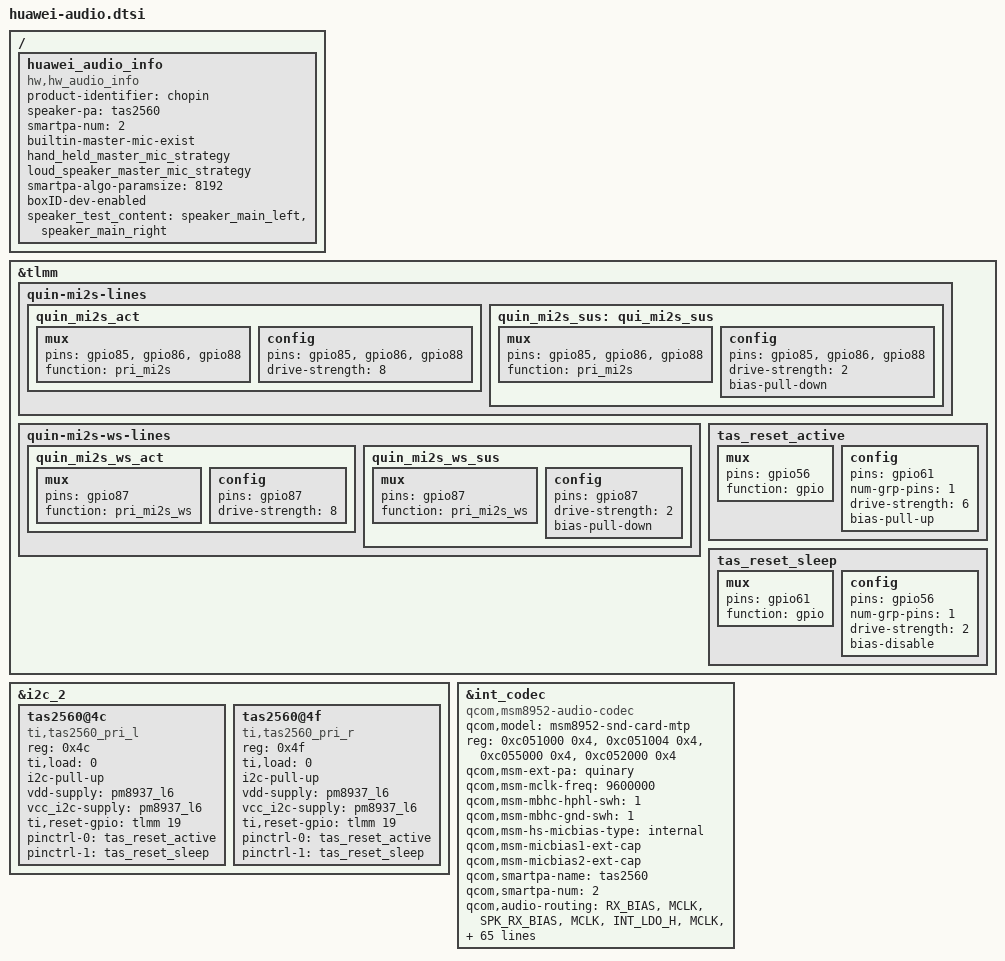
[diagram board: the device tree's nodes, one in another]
/*
 * Copyright (c) 2016, The Linux Foundation. All rights reserved.
 *
 * This program is free software; you can redistribute it and/or modify
 * it under the terms of the GNU General Public License version 2 and
 * only version 2 as published by the Free Software Foundation.
 *
 * This program is distributed in the hope that it will be useful,
 * but WITHOUT ANY WARRANTY; without even the implied warranty of
 * MERCHANTABILITY or FITNESS FOR A PARTICULAR PURPOSE.  See the
 * GNU General Public License for more details.
 */
/{
	huawei_audio_info {
		compatible = "hw,hw_audio_info";
		product-identifier = "chopin";
		speaker-pa = "tas2560";
		smartpa-num = <2>;
		builtin-master-mic-exist;
		hand_held_master_mic_strategy;
		loud_speaker_master_mic_strategy;
		smartpa-algo-paramsize = <8192>;
		status = "ok";
		boxID-dev-enabled;		/* if use /dev/deviceboxID configure */
		/* list the all speakers name , if only one, set it to "speaker" */
		speaker_test_content = "speaker_main_left","speaker_main_right";
	};
};
&tlmm {
	quin-mi2s-lines {
		quin_mi2s_act: quin_mi2s_act {
			mux {
				pins = "gpio85", "gpio86", "gpio88";
				function = "pri_mi2s";
			};

			config {
				pins = "gpio85", "gpio86", "gpio88";
				drive-strength = <8>;
			};
		};

		quin_mi2s_sus: qui_mi2s_sus {
			mux {
				pins = "gpio85", "gpio86", "gpio88";
				function = "pri_mi2s";
			};

			config {
				pins = "gpio85", "gpio86", "gpio88";
				drive-strength = <2>;
				bias-pull-down;
			};
		};
	};

	quin-mi2s-ws-lines {
		quin_mi2s_ws_act: quin_mi2s_ws_act {
			mux {
				pins = "gpio87";
				function = "pri_mi2s_ws";
			};

			config {
				pins = "gpio87";
				drive-strength = <8>;
			};
		};

		quin_mi2s_ws_sus: quin_mi2s_ws_sus {
			mux {
				pins = "gpio87";
				function = "pri_mi2s_ws";
			};

			config {
				pins = "gpio87";
				drive-strength = <2>;
				bias-pull-down;
			};
		};
	};

	tas_reset_active: tas_reset_active {
		mux {
			pins = "gpio56";
			function =  "gpio";
		};
		config {
			pins = "gpio61";
			num-grp-pins = <1>;
			drive-strength = <6>;
			bias-pull-up;
		};
	};

	tas_reset_sleep: tas_reset_sleep {
			mux {
				pins = "gpio61";
				function =  "gpio";
			};
			config {
				pins = "gpio56";
				num-grp-pins = <1>;
				drive-strength = <2>;
				bias-disable;
		};
	};
};
&i2c_2 {
	/delete-node/ wsa881x-i2c-codec@e;
	/delete-node/ wsa881x-i2c-codec@44;
	/delete-node/ wsa881x-i2c-codec@f;
	/delete-node/ wsa881x-i2c-codec@45;
	tas2560@4c {
		compatible = "ti,tas2560_pri_l";
		reg = <0x4c>;
		ti,load = <0>;   /* 0, 8Ohm; 1, 6Ohm; 2, 4Ohm */
		i2c-pull-up;
		vdd-supply = <&pm8937_l6>;
		vcc_i2c-supply = <&pm8937_l6>;
		ti,reset-gpio = <&tlmm 19 0>;
		pinctrl-names = "tas_active","tas_suspend";
		pinctrl-0 = <&tas_reset_active>;
		pinctrl-1 = <&tas_reset_sleep>;
	};

	tas2560@4f {
		compatible = "ti,tas2560_pri_r";
		reg = <0x4f>;
		ti,load = <0>;   /* 0, 8Ohm; 1, 6Ohm; 2, 4Ohm */
		i2c-pull-up;
		vdd-supply = <&pm8937_l6>;
		vcc_i2c-supply = <&pm8937_l6>;
		ti,reset-gpio = <&tlmm 19 0>;
		pinctrl-names = "tas_active","tas_suspend";
		pinctrl-0 = <&tas_reset_active>;
		pinctrl-1 = <&tas_reset_sleep>;
	};

};
&int_codec {
	/delete-property/ qcom,cdc-us-euro-gpios;

	compatible = "qcom,msm8952-audio-codec";
	qcom,model = "msm8952-snd-card-mtp";

	reg = <0xc051000 0x4>,
		<0xc051004 0x4>,
		<0xc055000 0x4>,
		<0xc052000 0x4>;
	reg-names = "csr_gp_io_mux_mic_ctl",
		"csr_gp_io_mux_spkr_ctl",
		"csr_gp_io_lpaif_pri_pcm_pri_mode_muxsel",
		"csr_gp_io_mux_quin_ctl";

	qcom,msm-ext-pa = "quinary";
	qcom,msm-mclk-freq = <9600000>;
	qcom,msm-mbhc-hphl-swh = <1>;
	qcom,msm-mbhc-gnd-swh = <1>;
	qcom,msm-hs-micbias-type = "internal";
	qcom,msm-micbias1-ext-cap;
	qcom,msm-micbias2-ext-cap;
	qcom,smartpa-name = "tas2560";
	qcom,smartpa-num = <2>;
	qcom,audio-routing =
		"RX_BIAS", "MCLK",
		"SPK_RX_BIAS", "MCLK",
		"INT_LDO_H", "MCLK",
		"MIC BIAS External", "Handset Mic",
		"MIC BIAS Internal2", "Headset Mic",
		"AMIC1", "MIC BIAS External",
		"AMIC2", "MIC BIAS Internal2";

	qcom,msm-gpios =
		"pri_i2s",
		"quin_i2s",
		"quat_i2s";
	qcom,pinctrl-names =
		"all_off",
		"pri_i2s_act",
		"quin_i2s_act",
		"pri_i2s_quin_i2s_act",
		"quat_i2s_act",
		"quat_i2s_pri_i2s_act",
		"quin_i2s_quat_i2s_act",
		"quin_i2s_quat_i2s_pri_i2s_act";
	pinctrl-names =
		"all_off",
		"pri_i2s_act",
		"quin_i2s_act",
		"pri_i2s_quin_i2s_act",
		"quat_i2s_act",
		"quat_i2s_pri_i2s_act",
		"quin_i2s_quat_i2s_act",
		"quin_i2s_quat_i2s_pri_i2s_act";
	pinctrl-0 = <&cdc_pdm_lines_sus &cdc_pdm_lines_2_sus
		&quin_mi2s_sus &quin_mi2s_ws_sus >;
	pinctrl-1 = <&cdc_pdm_lines_act &cdc_pdm_lines_2_act
		&quin_mi2s_sus &quin_mi2s_ws_sus >;
	pinctrl-2 = <&cdc_pdm_lines_sus &cdc_pdm_lines_2_sus
		&quin_mi2s_act &quin_mi2s_ws_act >;
	pinctrl-3 = <&cdc_pdm_lines_act &cdc_pdm_lines_2_act
		&quin_mi2s_act &quin_mi2s_ws_act >;
	pinctrl-4 = <&cdc_pdm_lines_sus &cdc_pdm_lines_2_sus
		&quin_mi2s_sus &quin_mi2s_ws_sus >;
	pinctrl-5 = <&cdc_pdm_lines_act &cdc_pdm_lines_2_act
		&quin_mi2s_sus &quin_mi2s_ws_sus >;
	pinctrl-6 = <&cdc_pdm_lines_sus &cdc_pdm_lines_2_sus
		&quin_mi2s_act &quin_mi2s_ws_act >;
	pinctrl-7 = <&cdc_pdm_lines_act &cdc_pdm_lines_2_act
		&quin_mi2s_act &quin_mi2s_ws_act >;

	asoc-platform = <&pcm0>, <&pcm1>, <&pcm2>, <&voip>, <&voice>,
		<&loopback>, <&compress>, <&hostless>,
		<&afe>, <&lsm>, <&routing>, <&lpa>;
	asoc-platform-names = "msm-pcm-dsp.0", "msm-pcm-dsp.1",
		"msm-pcm-dsp.2", "msm-voip-dsp",
		"msm-pcm-voice", "msm-pcm-loopback",
		"msm-compress-dsp", "msm-pcm-hostless",
		"msm-pcm-afe", "msm-lsm-client",
		"msm-pcm-routing", "msm-pcm-lpa";
	asoc-cpu = <&dai_pri_auxpcm>,
	<&dai_mi2s0>, <&dai_mi2s1>,
	<&dai_mi2s2>, <&dai_mi2s3>,
	<&dai_mi2s5>, <&dai_mi2s6>,
	<&sb_0_rx>, <&sb_0_tx>, <&sb_1_rx>, <&sb_1_tx>,
	<&sb_3_rx>, <&sb_3_tx>, <&sb_4_rx>, <&sb_4_tx>,
	<&bt_sco_rx>, <&bt_sco_tx>,
	<&int_fm_rx>, <&int_fm_tx>,
	<&afe_pcm_rx>, <&afe_pcm_tx>,
	<&afe_proxy_rx>, <&afe_proxy_tx>,
	<&incall_record_rx>, <&incall_record_tx>,
	<&incall_music_rx>, <&incall_music_2_rx>;
	asoc-cpu-names = "msm-dai-q6-auxpcm.1",
		"msm-dai-q6-mi2s.0", "msm-dai-q6-mi2s.1",
		"msm-dai-q6-mi2s.2", "msm-dai-q6-mi2s.3",
		"msm-dai-q6-mi2s.5", "msm-dai-q6-mi2s.6",
		"msm-dai-q6-dev.16384", "msm-dai-q6-dev.16385",
		"msm-dai-q6-dev.16386", "msm-dai-q6-dev.16387",
		"msm-dai-q6-dev.16390", "msm-dai-q6-dev.16391",
		"msm-dai-q6-dev.16392", "msm-dai-q6-dev.16393",
		"msm-dai-q6-dev.12288", "msm-dai-q6-dev.12289",
		"msm-dai-q6-dev.12292", "msm-dai-q6-dev.12293",
		"msm-dai-q6-dev.224", "msm-dai-q6-dev.225",
		"msm-dai-q6-dev.241", "msm-dai-q6-dev.240",
		"msm-dai-q6-dev.32771", "msm-dai-q6-dev.32772",
		"msm-dai-q6-dev.32773", "msm-dai-q6-dev.32770";
};
